# EFM32GG11B840F1024GL192 register map
File version: 4.0.0
CPU: CM4 r0p1, little endian, MPU, FPU, 3 interrupt priority bits
Registers are 32-bit, read-write, reset 0x0 unless marked. A register's access mark holds for its fields unless they carry their own. Offsets are from the block's base; [hi:lo] are bit positions; {n}, {i} and the like mark numbered series; 'fields as' and 'values as' point back to an identical list.

## EMU
Base 0x400E3000
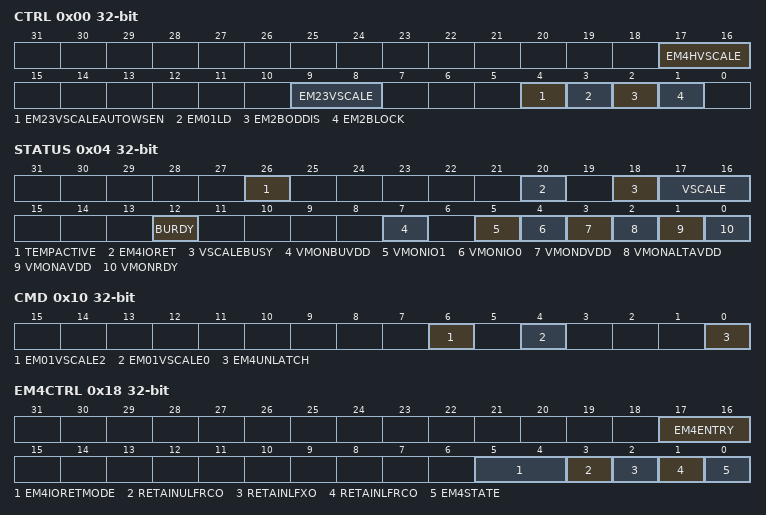
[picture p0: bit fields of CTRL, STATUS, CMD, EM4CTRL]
0x00 CTRL — Control Register
  [17:16] EM4HVSCALE — EM4H Voltage Scale
    0=VSCALE2 (Voltage Scale Level 2); 2=VSCALE0 (Voltage Scale Level 0)
  [9:8] EM23VSCALE — EM23 Voltage Scale
    values as EM4HVSCALE
  [4] EM23VSCALEAUTOWSEN — Automatically Configures Flash and Frequency to Wakeup From EM2 or EM3 at Low Voltage
  [3] EM01LD — Reserved for internal use. Do not change.
  [2] EM2BODDIS — Disable BOD in EM2
  [1] EM2BLOCK — Energy Mode 2 Block
0x04 STATUS ro
  [26] TEMPACTIVE — Temperature Measurement Active
  [20] EM4IORET — IO Retention Status
  [18] VSCALEBUSY — System is Busy Scaling Voltage
  [17:16] VSCALE — Current Voltage Scale Value
    0=Voltage Scale Level 2; 2=Voltage Scale Level 0
  [12] BURDY — Backup Mode Ready
  [7] VMONBUVDD — VMON BUVDD Channel
  [5] VMONIO1 — VMON IOVDD1 Channel
  [4] VMONIO0 — VMON IOVDD0 Channel
  [3] VMONDVDD — VMON DVDD Channel
  [2] VMONALTAVDD — Alternate VMON AVDD Channel
  [1] VMONAVDD — VMON AVDD Channel
  [0] VMONRDY — VMON Ready
0x08 LOCK — Configuration Lock Register
  [15:0] LOCKKEY — Configuration Lock Key
    0=UNLOCKED; 1=LOCKED
0x0C RAM0CTRL — Memory Control Register
  [6:0] RAMPOWERDOWN — RAM0 Blockset Power-down
    0=NONE (None of the RAM blocks powered down); 64=BLK7 (Power down RAM block 7 and above); 96=BLK6TO7 (Power down RAM block 6 and above); 112=BLK5TO7 (Power down RAM block 5 and above); 120=BLK4TO7 (Power down RAM blocks 4 and above); 124=BLK3TO7 (Power down RAM blocks 3 and above); 126=BLK2TO7 (Power down RAM blocks 2 and above); 127=BLK1TO7 (Power down RAM blocks 1 and above)
0x10 CMD wo — Command Register
  [6] EM01VSCALE2 — EM01 Voltage Scale Command to Scale to Voltage Scale Level 2
  [4] EM01VSCALE0 — EM01 Voltage Scale Command to Scale to Voltage Scale Level 0
  [0] EM4UNLATCH
0x18 EM4CTRL — EM4 Control Register
  [17:16] EM4ENTRY wo — Energy Mode 4 Entry
  [5:4] EM4IORETMODE — EM4 IO Retention Disable
    0=DISABLE (No Retention: Pads enter reset state when entering EM4); 1=EM4EXIT (Retention through EM4: Pads enter reset state when exiting EM4); 2=SWUNLATCH (Retention through EM4 and Wakeup: software writes UNLATCH register to remove retention)
  [3] RETAINULFRCO — ULFRCO Retain During EM4S
  [2] RETAINLFXO — LFXO Retain During EM4
  [1] RETAINLFRCO — LFRCO Retain During EM4
  [0] EM4STATE — Energy Mode 4 State
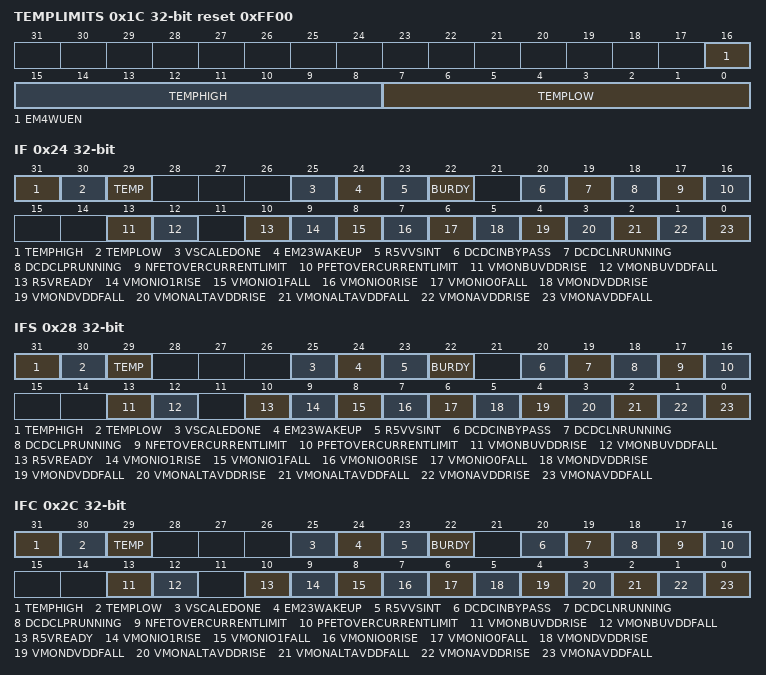
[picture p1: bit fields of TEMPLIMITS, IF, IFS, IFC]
0x1C TEMPLIMITS reset 0xFF00 — Temperature Limits for Interrupt Generation
  [16] EM4WUEN — Enable EM4 Wakeup Due to Low/high Temperature
  [15:8] TEMPHIGH — Temperature High Limit
  [7:0] TEMPLOW — Temperature Low Limit
0x20 TEMP ro — Value of Last Temperature Measurement
  [7:0] TEMP — Temperature Measurement
0x24 IF ro — Interrupt Flag Register
  [31] TEMPHIGH — Temperature High Limit Reached
  [30] TEMPLOW — Temperature Low Limit Reached
  [29] TEMP — New Temperature Measurement Valid
  [25] VSCALEDONE — Voltage Scale Steps Done IRQ
  [24] EM23WAKEUP — Wakeup IRQ From EM2 and EM3
  [23] R5VVSINT — 5V Regulator Voltage Update Done
  [22] BURDY — Backup Functionality Ready Interrupt Flag
  [20] DCDCINBYPASS — DCDC is in Bypass
  [19] DCDCLNRUNNING — LN Mode is Running
  [18] DCDCLPRUNNING — LP Mode is Running
  [17] NFETOVERCURRENTLIMIT — NFET Current Limit Hit
  [16] PFETOVERCURRENTLIMIT — PFET Current Limit Hit
  [13] VMONBUVDDRISE — VMON BUVDD Channel Rise
  [12] VMONBUVDDFALL — VMON BACKUP Channel Fall
  [10] R5VREADY — 5V Regulator is Ready to Use
  [9] VMONIO1RISE — VMON IOVDD1 Channel Rise
  [8] VMONIO1FALL — VMON IOVDD1 Channel Fall
  [7] VMONIO0RISE — VMON IOVDD0 Channel Rise
  [6] VMONIO0FALL — VMON IOVDD0 Channel Fall
  [5] VMONDVDDRISE — VMON DVDD Channel Rise
  [4] VMONDVDDFALL — VMON DVDD Channel Fall
  [3] VMONALTAVDDRISE — Alternate VMON AVDD Channel Rise
  [2] VMONALTAVDDFALL — Alternate VMON AVDD Channel Fall
  [1] VMONAVDDRISE — VMON AVDD Channel Rise
  [0] VMONAVDDFALL — VMON AVDD Channel Fall
0x28 IFS wo — Interrupt Flag Set Register
  [31] TEMPHIGH — Set TEMPHIGH Interrupt Flag
  [30] TEMPLOW — Set TEMPLOW Interrupt Flag
  [29] TEMP — Set TEMP Interrupt Flag
  [25] VSCALEDONE — Set VSCALEDONE Interrupt Flag
  [24] EM23WAKEUP — Set EM23WAKEUP Interrupt Flag
  [23] R5VVSINT — Set R5VVSINT Interrupt Flag
  [22] BURDY — Set BURDY Interrupt Flag
  [20] DCDCINBYPASS — Set DCDCINBYPASS Interrupt Flag
  [19] DCDCLNRUNNING — Set DCDCLNRUNNING Interrupt Flag
  [18] DCDCLPRUNNING — Set DCDCLPRUNNING Interrupt Flag
  [17] NFETOVERCURRENTLIMIT — Set NFETOVERCURRENTLIMIT Interrupt Flag
  [16] PFETOVERCURRENTLIMIT — Set PFETOVERCURRENTLIMIT Interrupt Flag
  [13] VMONBUVDDRISE — Set VMONBUVDDRISE Interrupt Flag
  [12] VMONBUVDDFALL — Set VMONBUVDDFALL Interrupt Flag
  [10] R5VREADY — Set R5VREADY Interrupt Flag
  [9] VMONIO1RISE — Set VMONIO1RISE Interrupt Flag
  [8] VMONIO1FALL — Set VMONIO1FALL Interrupt Flag
  [7] VMONIO0RISE — Set VMONIO0RISE Interrupt Flag
  [6] VMONIO0FALL — Set VMONIO0FALL Interrupt Flag
  [5] VMONDVDDRISE — Set VMONDVDDRISE Interrupt Flag
  [4] VMONDVDDFALL — Set VMONDVDDFALL Interrupt Flag
  [3] VMONALTAVDDRISE — Set VMONALTAVDDRISE Interrupt Flag
  [2] VMONALTAVDDFALL — Set VMONALTAVDDFALL Interrupt Flag
  [1] VMONAVDDRISE — Set VMONAVDDRISE Interrupt Flag
  [0] VMONAVDDFALL — Set VMONAVDDFALL Interrupt Flag
0x2C IFC wo — Interrupt Flag Clear Register
  [31] TEMPHIGH — Clear TEMPHIGH Interrupt Flag
  [30] TEMPLOW — Clear TEMPLOW Interrupt Flag
  [29] TEMP — Clear TEMP Interrupt Flag
  [25] VSCALEDONE — Clear VSCALEDONE Interrupt Flag
  [24] EM23WAKEUP — Clear EM23WAKEUP Interrupt Flag
  [23] R5VVSINT — Clear R5VVSINT Interrupt Flag
  [22] BURDY — Clear BURDY Interrupt Flag
  [20] DCDCINBYPASS — Clear DCDCINBYPASS Interrupt Flag
  [19] DCDCLNRUNNING — Clear DCDCLNRUNNING Interrupt Flag
  [18] DCDCLPRUNNING — Clear DCDCLPRUNNING Interrupt Flag
  [17] NFETOVERCURRENTLIMIT — Clear NFETOVERCURRENTLIMIT Interrupt Flag
  [16] PFETOVERCURRENTLIMIT — Clear PFETOVERCURRENTLIMIT Interrupt Flag
  [13] VMONBUVDDRISE — Clear VMONBUVDDRISE Interrupt Flag
  [12] VMONBUVDDFALL — Clear VMONBUVDDFALL Interrupt Flag
  [10] R5VREADY — Clear R5VREADY Interrupt Flag
  [9] VMONIO1RISE — Clear VMONIO1RISE Interrupt Flag
  [8] VMONIO1FALL — Clear VMONIO1FALL Interrupt Flag
  [7] VMONIO0RISE — Clear VMONIO0RISE Interrupt Flag
  [6] VMONIO0FALL — Clear VMONIO0FALL Interrupt Flag
  [5] VMONDVDDRISE — Clear VMONDVDDRISE Interrupt Flag
  [4] VMONDVDDFALL — Clear VMONDVDDFALL Interrupt Flag
  [3] VMONALTAVDDRISE — Clear VMONALTAVDDRISE Interrupt Flag
  [2] VMONALTAVDDFALL — Clear VMONALTAVDDFALL Interrupt Flag
  [1] VMONAVDDRISE — Clear VMONAVDDRISE Interrupt Flag
  [0] VMONAVDDFALL — Clear VMONAVDDFALL Interrupt Flag
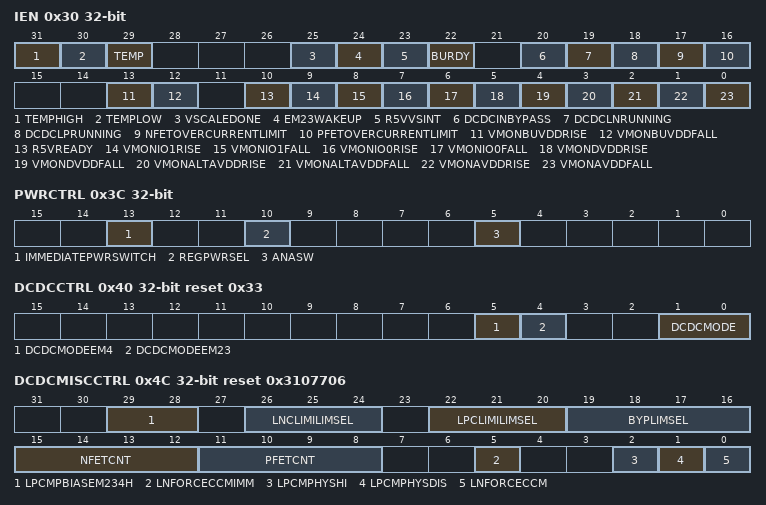
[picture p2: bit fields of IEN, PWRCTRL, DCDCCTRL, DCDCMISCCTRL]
0x30 IEN — Interrupt Enable Register
  [31] TEMPHIGH — TEMPHIGH Interrupt Enable
  [30] TEMPLOW — TEMPLOW Interrupt Enable
  [29] TEMP — TEMP Interrupt Enable
  [25] VSCALEDONE — VSCALEDONE Interrupt Enable
  [24] EM23WAKEUP — EM23WAKEUP Interrupt Enable
  [23] R5VVSINT — R5VVSINT Interrupt Enable
  [22] BURDY — BURDY Interrupt Enable
  [20] DCDCINBYPASS — DCDCINBYPASS Interrupt Enable
  [19] DCDCLNRUNNING — DCDCLNRUNNING Interrupt Enable
  [18] DCDCLPRUNNING — DCDCLPRUNNING Interrupt Enable
  [17] NFETOVERCURRENTLIMIT — NFETOVERCURRENTLIMIT Interrupt Enable
  [16] PFETOVERCURRENTLIMIT — PFETOVERCURRENTLIMIT Interrupt Enable
  [13] VMONBUVDDRISE — VMONBUVDDRISE Interrupt Enable
  [12] VMONBUVDDFALL — VMONBUVDDFALL Interrupt Enable
  [10] R5VREADY — R5VREADY Interrupt Enable
  [9] VMONIO1RISE — VMONIO1RISE Interrupt Enable
  [8] VMONIO1FALL — VMONIO1FALL Interrupt Enable
  [7] VMONIO0RISE — VMONIO0RISE Interrupt Enable
  [6] VMONIO0FALL — VMONIO0FALL Interrupt Enable
  [5] VMONDVDDRISE — VMONDVDDRISE Interrupt Enable
  [4] VMONDVDDFALL — VMONDVDDFALL Interrupt Enable
  [3] VMONALTAVDDRISE — VMONALTAVDDRISE Interrupt Enable
  [2] VMONALTAVDDFALL — VMONALTAVDDFALL Interrupt Enable
  [1] VMONAVDDRISE — VMONAVDDRISE Interrupt Enable
  [0] VMONAVDDFALL — VMONAVDDFALL Interrupt Enable
0x34 PWRLOCK — Regulator and Supply Lock Register
  [15:0] LOCKKEY — Regulator and Supply Configuration Lock Key
    0=UNLOCKED; 1=LOCKED
0x3C PWRCTRL — Power Control Register
  [13] IMMEDIATEPWRSWITCH — Allows Immediate Switching of ANASW and REGPWRSEL Bitfields
  [10] REGPWRSEL — This Field Selects the Input Supply Pin for the Digital LDO
  [5] ANASW — Analog Switch Selection
0x40 DCDCCTRL reset 0x33 — DCDC Control
  [5] DCDCMODEEM4 — DCDC Mode EM4H
  [4] DCDCMODEEM23
  [1:0] DCDCMODE — Regulator Mode
    0=BYPASS (DCDC regulator is operating in bypass mode. Prior to configuring DCDCMODE=BYPASS, software must set EMU_DCDCCLIMCTRL.BYPLIMEN=1 to prevent excessive current between VREGVDD and DVDD supplies.); 1=LOWNOISE (DCDC regulator is operating in low noise mode.); 2=LOWPOWER (DCDC regulator is operating in low power mode.); 3=OFF (DCDC regulator is off and the bypass switch is off. Note: DVDD must be supplied externally)
0x4C DCDCMISCCTRL reset 0x3107706 — DCDC Miscellaneous Control Register
  [29:28] LPCMPBIASEM234H — LP Mode Comparator Bias Selection for EM23 or EM4H
    0=BIAS0 (Maximum load current less than 75uA.); 1=BIAS1 (Maximum load current less than 500uA.); 2=BIAS2 (Maximum load current less than 2.5mA.); 3=BIAS3 (Maximum load current less than 10mA.)
  [26:24] LNCLIMILIMSEL — Current Limit Level Selection for Current Limiter in LN Mode
  [22:20] LPCLIMILIMSEL — Current Limit Level Selection for Current Limiter in LP Mode
  [19:16] BYPLIMSEL — Current Limit in Bypass Mode
  [15:12] NFETCNT — NFET Switch Number Selection
  [11:8] PFETCNT — PFET Switch Number Selection
  [5] LNFORCECCMIMM — Force DCDC Into CCM Mode Immediately, Based on LNFORCECCM
  [2] LPCMPHYSHI — Comparator Threshold on the High Side
  [1] LPCMPHYSDIS — Disable LP Mode Hysteresis in the State Machine Control
  [0] LNFORCECCM — Force DCDC Into CCM Mode in Low Noise Operation
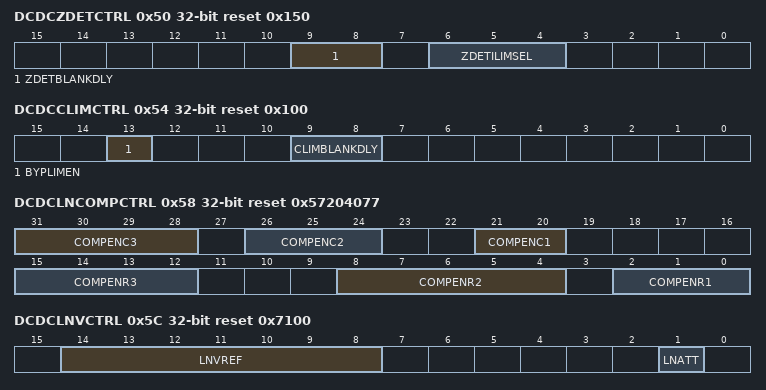
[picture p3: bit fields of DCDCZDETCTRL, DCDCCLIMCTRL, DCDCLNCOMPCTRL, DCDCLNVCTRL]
0x50 DCDCZDETCTRL reset 0x150 — DCDC Power Train NFET Zero Current Detector Control Register
  [9:8] ZDETBLANKDLY — Reserved for internal use. Do not change.
  [6:4] ZDETILIMSEL — Reverse Current Limit Level Selection for Zero Detector
0x54 DCDCCLIMCTRL reset 0x100 — DCDC Power Train PFET Current Limiter Control Register
  [13] BYPLIMEN — Bypass Current Limit Enable
  [9:8] CLIMBLANKDLY — Reserved for internal use. Do not change.
0x58 DCDCLNCOMPCTRL reset 0x57204077 — DCDC Low Noise Compensator Control Register
  [31:28] COMPENC3 — Low Noise Mode Compensator C3 Trim Value
  [26:24] COMPENC2 — Low Noise Mode Compensator C2 Trim Value
  [21:20] COMPENC1 — Low Noise Mode Compensator C1 Trim Value
  [15:12] COMPENR3 — Low Noise Mode Compensator R3 Trim Value
  [8:4] COMPENR2 — Low Noise Mode Compensator R2 Trim Value
  [2:0] COMPENR1 — Low Noise Mode Compensator R1 Trim Value
0x5C DCDCLNVCTRL reset 0x7100 — DCDC Low Noise Voltage Register
  [14:8] LNVREF — Low Noise Mode VREF Trim
  [1] LNATT — Low Noise Mode Feedback Attenuation
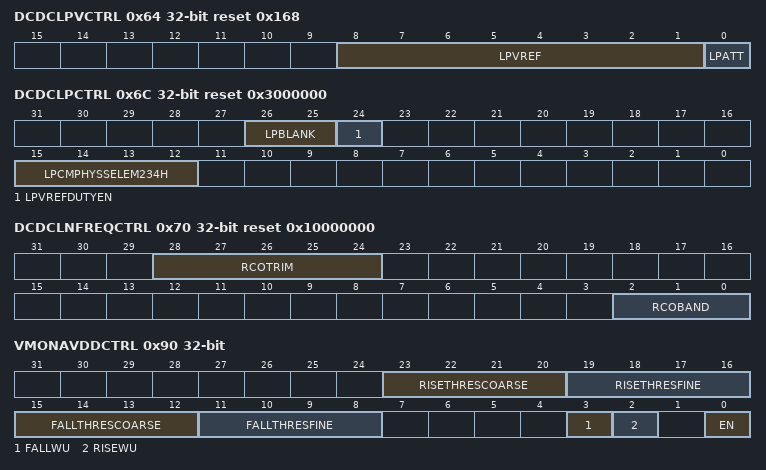
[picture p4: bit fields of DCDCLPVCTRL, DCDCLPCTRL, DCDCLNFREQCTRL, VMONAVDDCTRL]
0x64 DCDCLPVCTRL reset 0x168 — DCDC Low Power Voltage Register
  [8:1] LPVREF — LP Mode Reference Selection for EM23 and EM4H
  [0] LPATT — Low Power Feedback Attenuation
0x6C DCDCLPCTRL reset 0x3000000 — DCDC Low Power Control Register
  [26:25] LPBLANK — Reserved for internal use. Do not change.
  [24] LPVREFDUTYEN — LP Mode Duty Cycling Enable
  [15:12] LPCMPHYSSELEM234H — LP Mode Hysteresis Selection for EM23 and EM4H
0x70 DCDCLNFREQCTRL reset 0x10000000 — DCDC Low Noise Controller Frequency Control
  [28:24] RCOTRIM — Reserved for internal use. Do not change.
  [2:0] RCOBAND — LN Mode RCO Frequency Band Selection
0x78 DCDCSYNC ro — DCDC Read Status Register
  [0] DCDCCTRLBUSY — DCDC CTRL Register Transfer Busy
0x90 VMONAVDDCTRL — VMON AVDD Channel Control
  [23:20] RISETHRESCOARSE — Rising Threshold Coarse Adjust
  [19:16] RISETHRESFINE — Rising Threshold Fine Adjust
  [15:12] FALLTHRESCOARSE — Falling Threshold Coarse Adjust
  [11:8] FALLTHRESFINE — Falling Threshold Fine Adjust
  [3] FALLWU — Fall Wakeup
  [2] RISEWU — Rise Wakeup
  [0] EN — Enable
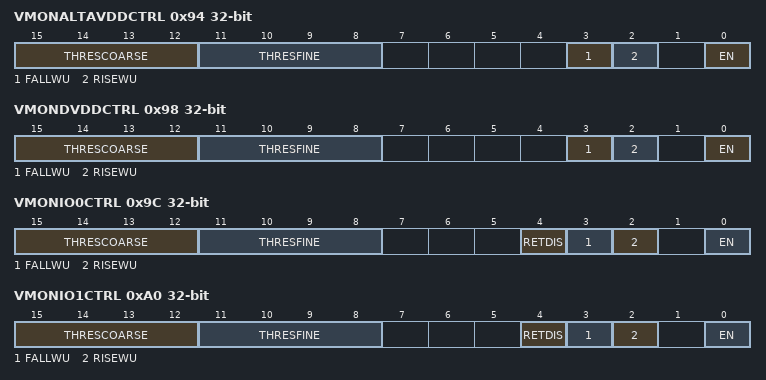
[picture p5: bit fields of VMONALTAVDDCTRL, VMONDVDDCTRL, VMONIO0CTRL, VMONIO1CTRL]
0x94 VMONALTAVDDCTRL — Alternate VMON AVDD Channel Control
  [15:12] THRESCOARSE — Threshold Coarse Adjust
  [11:8] THRESFINE — Threshold Fine Adjust
  [3] FALLWU — Fall Wakeup
  [2] RISEWU — Rise Wakeup
  [0] EN — Enable
0x98 VMONDVDDCTRL — VMON DVDD Channel Control
  fields as VMONALTAVDDCTRL
0x9C VMONIO0CTRL — VMON IOVDD0 Channel Control
  [15:12] THRESCOARSE — Threshold Coarse Adjust
  [11:8] THRESFINE — Threshold Fine Adjust
  [4] RETDIS — EM4 IO0 Retention Disable
  [3] FALLWU — Fall Wakeup
  [2] RISEWU — Rise Wakeup
  [0] EN — Enable
0xA0 VMONIO1CTRL — VMON IOVDD1 Channel Control
  [15:12] THRESCOARSE — Threshold Coarse Adjust
  [11:8] THRESFINE — Threshold Fine Adjust
  [4] RETDIS — EM4 IO1 Retention Disable
  [3] FALLWU — Fall Wakeup
  [2] RISEWU — Rise Wakeup
  [0] EN — Enable
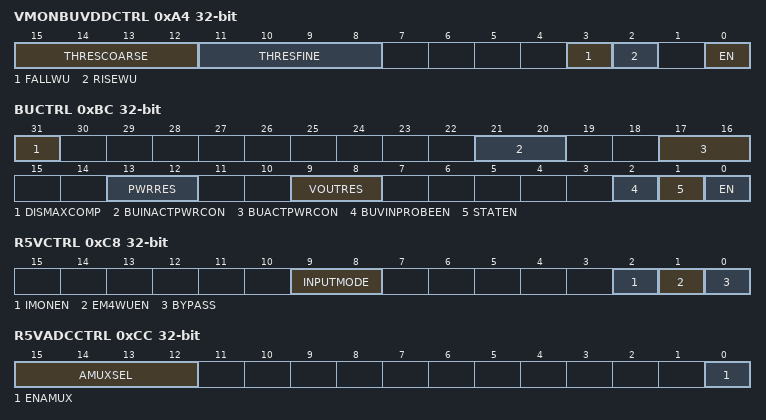
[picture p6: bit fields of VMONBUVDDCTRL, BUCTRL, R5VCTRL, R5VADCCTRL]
0xA4 VMONBUVDDCTRL — VMON BUVDD Channel Control
  fields as VMONALTAVDDCTRL
0xB4 RAM1CTRL — Memory Control Register
  [7:0] RAMPOWERDOWN — RAM1 Blockset Power-down
    0=NONE (None of the RAM blocks powered down); 128=BLK7 (Power down RAM block 7 (address range 0x2003C000-0x2003FFFF)); 192=BLK6TO7 (Power down RAM blocks 6-7 (address range 0x20038000-0x2003FFFF)); 224=BLK5TO7 (Power down RAM blocks 5-7 (address range 0x20034000-0x2003FFFF)); 240=BLK4TO7 (Power down RAM blocks 4-7 (address range 0x20030000-0x2003FFFF)); 248=BLK3TO7 (Power down RAM blocks 3-7 (address range 0x2002C000-0x2003FFFF)); 252=BLK2TO7 (Power down RAM blocks 2-7 (address range 0x20028000-0x2003FFFF)); 254=BLK1TO7 (Power down RAM blocks 1-7 (address range 0x20024000-0x2003FFFF)); 255=BLK0TO7 (Power down RAM blocks 0-7 (address range 0x20020000-0x2003FFFF))
0xB8 RAM2CTRL — Memory Control Register
  [3:0] RAMPOWERDOWN — RAM2 Blockset Power-down
    0=NONE (None of the RAM blocks powered down); 8=BLK3 (Power down RAM block 3); 12=BLK2TO3 (Power down RAM blocks 2-3); 14=BLK1TO3 (Power down RAM blocks 1-3); 15=BLK0TO3 (Power down RAM blocks 0-3)
0xBC BUCTRL — Backup Power Configuration Register
  [31] DISMAXCOMP — Disable MAIN-BU Comparator
  [21:20] BUINACTPWRCON — Power Connection Configuration When Not in Backup Mode
    0=NONE (No connection.); 1=MAINBU (Main power and backup power are connected through a diode, allowing current to flow from main power source to backup power source, but not the other way.); 2=BUMAIN (Main power and backup power are connected through a diode, allowing current to flow from backup power source to main power source, but not the other way.); 3=NODIODE (Main power and backup power are connected without diode.)
  [17:16] BUACTPWRCON — Power Connection Configuration in Backup Mode
    0=NONE (No connection.); 1=MAINBU (Main power and backup power are connected through a diode, allowing current to flow from backup power source to main power source, but not the other way.); 2=BUMAIN (Main power and backup power are connected through a diode, allowing current to flow from main power source to backup power source, but not the other way.); 3=NODIODE (Main power and backup power are connected without diode.)
  [13:12] PWRRES — Power Domain Resistor Select
    {v}=RES{v} (Main power and backup power connected with RES{v} series resistance.) (v=0..3)
  [9:8] VOUTRES — BU_VOUT Resistor Select
    0=DIS (BU_VOUT is not connected); 1=WEAK (Enable weak switch between BU_VOUT and backup domain power supply.); 2=MED (Enable medium switch between BU_VOUT and backup domain power supply.); 3=STRONG (Enable strong switch between BU_VOUT and backup domain power supply.)
  [2] BUVINPROBEEN — Enable BU_VIN Probing
  [1] STATEN — Enable Backup Mode Status Export
  [0] EN — Enable Backup Mode
0xC8 R5VCTRL — 5V Regulator Control
  [9:8] INPUTMODE — 5V Input Mode
    0=AUTO (Regulator input supply switched automatically to the highest voltage of either VBUS or VREGI); 1=VBUS (Force VBUS pin as the regulator input); 2=VREGI (Force VREGI pin as the regulator input)
  [2] IMONEN — Enable the Regulator Current Monitor for Selected Current Path to Either VREGI or VBUS
  [1] EM4WUEN — Enable EM4 Wakeup Due to VBUS Detection
  [0] BYPASS — 5V Regulator Bypass
0xCC R5VADCCTRL — 5V Regulator Control
  [15:12] AMUXSEL — ADC Mux Selection
    0=VBUSDIV10 (VBUS divided by 10); 1=VREGIDIV10 (VREGI divided by 10); 2=VREGODIV6 (VREGO divided by 6); 3=VREGIIMON (VREGI current monitor); 4=VBUSIMON (VBUS current monitor)
  [0] ENAMUX — Enable the 5V Subsystem ADC MUX
0xD0 R5VOUTLEVEL reset 0x1 — 5V Regulator Voltage Select
  [3:0] OUTLEVEL — 5V Regulator Voltage
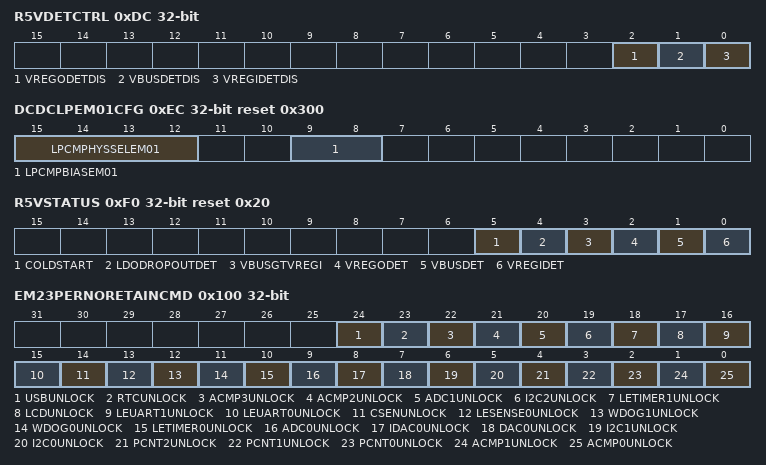
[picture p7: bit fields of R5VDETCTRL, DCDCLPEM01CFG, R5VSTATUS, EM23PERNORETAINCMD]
0xDC R5VDETCTRL — 5V Detector Enables
  [2] VREGODETDIS — VREGO Detector Disable
  [1] VBUSDETDIS — VBUS Detector Disable
  [0] VREGIDETDIS — VREGI Detector Disable
0xEC DCDCLPEM01CFG reset 0x300 — Configuration Bits for Low Power Mode to Be Applied During EM01, This Field is Only Relevant If LP Mode is Used in EM01
  [15:12] LPCMPHYSSELEM01 — LP Mode Hysteresis Selection for EM01
  [9:8] LPCMPBIASEM01 — LP Mode Comparator Bias Selection for EM01
    values as DCDCMISCCTRL.LPCMPBIASEM234H
0xF0 R5VSTATUS ro reset 0x20 — 5V Detector Status Register
  [5] COLDSTART — Indicates If the Regulator is Going Through a Cold Start
  [4] LDODROPOUTDET — Regulator Dropout Detection
  [3] VBUSGTVREGI — Output of the Supply Comparator Between VBUS and VREGI
  [2] VREGODET — VREGO Detected
  [1] VBUSDET — USB VBUS Detected
  [0] VREGIDET — VREGI Detected
0xF8 R5VSYNC ro — 5V Read Status Register
  [0] OUTLEVELBUSY — 5V Regulator Voltage Register Transfer Busy
0x100 EM23PERNORETAINCMD wo — Clears Corresponding Bits in EM23PERNORETAINSTATUS Unlocking Access to Peripheral
  [24] USBUNLOCK — Clears Status Bit of USB and Unlocks Access to It
  [23] RTCUNLOCK — Clears Status Bit of RTC and Unlocks Access to It
  [22] ACMP3UNLOCK — Clears Status Bit of ACMP3 and Unlocks Access to It
  [21] ACMP2UNLOCK — Clears Status Bit of ACMP2 and Unlocks Access to It
  [20] ADC1UNLOCK — Clears Status Bit of ADC1 and Unlocks Access to It
  [19] I2C2UNLOCK — Clears Status Bit of I2C2 and Unlocks Access to It
  [18] LETIMER1UNLOCK — Clears Status Bit of LETIMER1 and Unlocks Access to It
  [17] LCDUNLOCK — Clears Status Bit of LCD and Unlocks Access to It
  [16] LEUART1UNLOCK — Clears Status Bit of LEUART1 and Unlocks Access to It
  [15] LEUART0UNLOCK — Clears Status Bit of LEUART0 and Unlocks Access to It
  [14] CSENUNLOCK — Clears Status Bit of CSEN and Unlocks Access to It
  [13] LESENSE0UNLOCK — Clears Status Bit of LESENSE0 and Unlocks Access to It
  [12] WDOG1UNLOCK — Clears Status Bit of WDOG1 and Unlocks Access to It
  [11] WDOG0UNLOCK — Clears Status Bit of WDOG0 and Unlocks Access to It
  [10] LETIMER0UNLOCK — Clears Status Bit of LETIMER0 and Unlocks Access to It
  [9] ADC0UNLOCK — Clears Status Bit of ADC0 and Unlocks Access to It
  [8] IDAC0UNLOCK — Clears Status Bit of IDAC0 and Unlocks Access to It
  [7] DAC0UNLOCK — Clears Status Bit of DAC0 and Unlocks Access to It
  [6] I2C1UNLOCK — Clears Status Bit of I2C1 and Unlocks Access to It
  [5] I2C0UNLOCK — Clears Status Bit of I2C0 and Unlocks Access to It
  [4] PCNT2UNLOCK — Clears Status Bit of PCNT2 and Unlocks Access to It
  [3] PCNT1UNLOCK — Clears Status Bit of PCNT1 and Unlocks Access to It
  [2] PCNT0UNLOCK — Clears Status Bit of PCNT0 and Unlocks Access to It
  [1] ACMP1UNLOCK — Clears Status Bit of ACMP1 and Unlocks Access to It
  [0] ACMP0UNLOCK — Clears Status Bit of ACMP0 and Unlocks Access to It
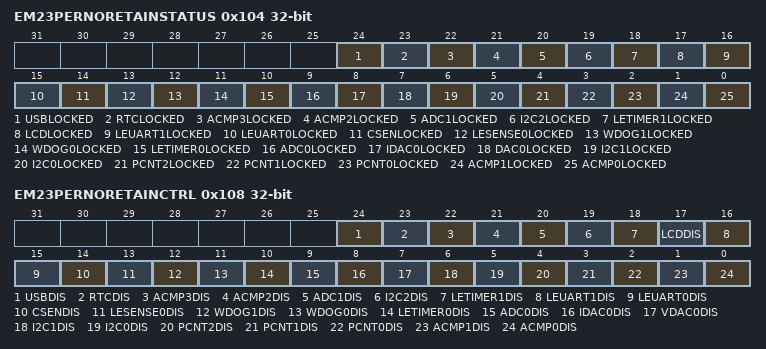
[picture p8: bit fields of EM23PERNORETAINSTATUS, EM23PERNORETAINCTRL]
0x104 EM23PERNORETAINSTATUS ro — Status Indicating If Peripherals Were Powered Down in EM23, Subsequently Locking Access to It
  [24] USBLOCKED — Indicates If USB Powered Down During EM23
  [23] RTCLOCKED — Indicates If RTC Powered Down During EM23
  [22] ACMP3LOCKED — Indicates If ACMP3 Powered Down During EM23
  [21] ACMP2LOCKED — Indicates If ACMP2 Powered Down During EM23
  [20] ADC1LOCKED — Indicates If ADC1 Powered Down During EM23
  [19] I2C2LOCKED — Indicates If I2C2 Powered Down During EM23
  [18] LETIMER1LOCKED — Indicates If LETIMER1 Powered Down During EM23
  [17] LCDLOCKED — Indicates If LCD Powered Down During EM23
  [16] LEUART1LOCKED — Indicates If LEUART1 Powered Down During EM23
  [15] LEUART0LOCKED — Indicates If LEUART0 Powered Down During EM23
  [14] CSENLOCKED — Indicates If CSEN Powered Down During EM23
  [13] LESENSE0LOCKED — Indicates If LESENSE0 Powered Down During EM23
  [12] WDOG1LOCKED — Indicates If WDOG1 Powered Down During EM23
  [11] WDOG0LOCKED — Indicates If WDOG0 Powered Down During EM23
  [10] LETIMER0LOCKED — Indicates If LETIMER0 Powered Down During EM23
  [9] ADC0LOCKED — Indicates If ADC0 Powered Down During EM23
  [8] IDAC0LOCKED — Indicates If IDAC0 Powered Down During EM23
  [7] DAC0LOCKED — Indicates If DAC0 Powered Down During EM23
  [6] I2C1LOCKED — Indicates If I2C1 Powered Down During EM23
  [5] I2C0LOCKED — Indicates If I2C0 Powered Down During EM23
  [4] PCNT2LOCKED — Indicates If PCNT2 Powered Down During EM23
  [3] PCNT1LOCKED — Indicates If PCNT1 Powered Down During EM23
  [2] PCNT0LOCKED — Indicates If PCNT0 Powered Down During EM23
  [1] ACMP1LOCKED — Indicates If ACMP1 Powered Down During EM23
  [0] ACMP0LOCKED — Indicates If ACMP0 Powered Down During EM23
0x108 EM23PERNORETAINCTRL — When Set Corresponding Peripherals May Get Powered Down in EM23
  [24] USBDIS — Allow Power Down of USB During EM23
  [23] RTCDIS — Allow Power Down of RTC During EM23
  [22] ACMP3DIS — Allow Power Down of ACMP3 During EM23
  [21] ACMP2DIS — Allow Power Down of ACMP2 During EM23
  [20] ADC1DIS — Allow Power Down of ADC1 During EM23
  [19] I2C2DIS — Allow Power Down of I2C2 During EM23
  [18] LETIMER1DIS — Allow Power Down of LETIMER1 During EM23
  [17] LCDDIS — Allow Power Down of LCD During EM23
  [16] LEUART1DIS — Allow Power Down of LEUART1 During EM23
  [15] LEUART0DIS — Allow Power Down of LEUART0 During EM23
  [14] CSENDIS — Allow Power Down of CSEN During EM23
  [13] LESENSE0DIS — Allow Power Down of LESENSE0 During EM23
  [12] WDOG1DIS — Allow Power Down of WDOG1 During EM23
  [11] WDOG0DIS — Allow Power Down of WDOG0 During EM23
  [10] LETIMER0DIS — Allow Power Down of LETIMER0 During EM23
  [9] ADC0DIS — Allow Power Down of ADC0 During EM23
  [8] IDAC0DIS — Allow Power Down of IDAC0 During EM23
  [7] VDAC0DIS — Allow Power Down of DAC0 During EM23
  [6] I2C1DIS — Allow Power Down of I2C1 During EM23
  [5] I2C0DIS — Allow Power Down of I2C0 During EM23
  [4] PCNT2DIS — Allow Power Down of PCNT2 During EM23
  [3] PCNT1DIS — Allow Power Down of PCNT1 During EM23
  [2] PCNT0DIS — Allow Power Down of PCNT0 During EM23
  [1] ACMP1DIS — Allow Power Down of ACMP1 During EM23
  [0] ACMP0DIS — Allow Power Down of ACMP0 During EM23

## Notices in the file
# License
Copyright 2021 Silicon Laboratories Inc. www.silabs.com
SPDX-License-Identifier: Zlib
The licensor of this software is Silicon Laboratories Inc.
This software is provided 'as-is', without any express or implied
warranty. In no event will the authors be held liable for any damages
arising from the use of this software.
Permission is granted to anyone to use this software for any purpose,
including commercial applications, and to alter it and redistribute it
freely, subject to the following restrictions:
1. The origin of this software must not be misrepresented; you must not
claim that you wrote the original software. If you use this software
in a product, an acknowledgment in the product documentation would be
appreciated but is not required.
2. Altered source versions must be plainly marked as such, and must not be
misrepresented as being the original software.
3. This notice may not be removed or altered from any source distribution.
